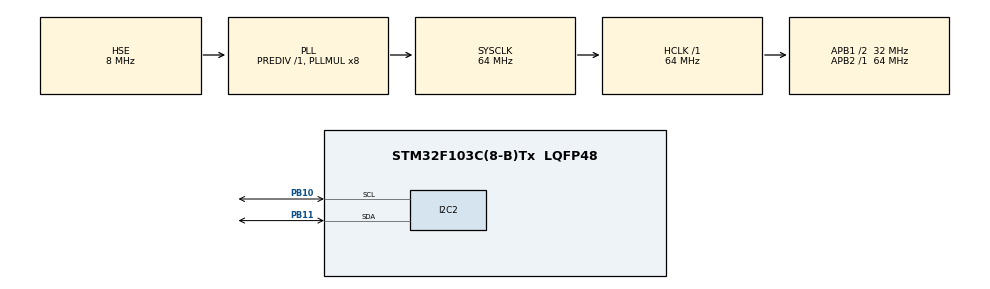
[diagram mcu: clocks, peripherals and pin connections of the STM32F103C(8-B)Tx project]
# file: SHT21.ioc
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Mcu.Family=STM32F1
Mcu.Name=STM32F103C(8-B)Tx
Mcu.Package=LQFP48
NVIC.PriorityGroup=NVIC_PRIORITYGROUP_4
PA13.Mode=Serial_Wire
PA13.Signal=SYS_JTMS-SWDIO
PA14.Mode=Serial_Wire
PA14.Signal=SYS_JTCK-SWCLK
PB10.Mode=I2C
PB10.Signal=I2C2_SCL
PB11.Mode=I2C
PB11.Signal=I2C2_SDA
PD0-OSC_IN.Mode=HSE-External-Oscillator
PD0-OSC_IN.Signal=RCC_OSC_IN
PD1-OSC_OUT.Mode=HSE-External-Oscillator
PD1-OSC_OUT.Signal=RCC_OSC_OUT
ProjectManager.HeapSize=0x2000
ProjectManager.StackSize=0x4000
ProjectManager.TargetToolchain=MDK-ARM V5.27
RCC.AHBFreq_Value=64000000
RCC.APB1CLKDivider=RCC_HCLK_DIV2
RCC.APB1Freq_Value=32000000
RCC.APB1TimFreq_Value=64000000
RCC.APB2Freq_Value=64000000
RCC.APB2TimFreq_Value=64000000
RCC.HCLKFreq_Value=64000000
RCC.PLLMUL=RCC_PLL_MUL8
RCC.PLLSourceVirtual=RCC_PLLSOURCE_HSE
RCC.SYSCLKFreq_VALUE=64000000
RCC.SYSCLKSource=RCC_SYSCLKSOURCE_PLLCLK
RCC.USBFreq_Value=64000000
board=custom

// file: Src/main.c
/* USER CODE BEGIN Header */
/**
  ******************************************************************************
  * @file           : main.c
  * @brief          : Main program body
  ******************************************************************************
  * @attention
  *
  * <h2><center>&copy; Copyright (c) 2020 STMicroelectronics.
  * All rights reserved.</center></h2>
  *
  * This software component is licensed by ST under BSD 3-Clause license,
  * the "License"; You may not use this file except in compliance with the
  * License. You may obtain a copy of the License at:
  *                        opensource.org/licenses/BSD-3-Clause
  *
  ******************************************************************************
  */
/* USER CODE END Header */

#include "main.h"

/* USER CODE BEGIN PD */
uint8_t ph = 0xf5;
uint8_t ud = 0xe7;
uint8_t t =0xf3;
uint8_t re = 0xFE;
/* USER CODE END PD */

I2C_HandleTypeDef hi2c2;

/* USER CODE BEGIN PV */
uint8_t phRXbuff[]={0x00, 0x00, 0x00};
uint8_t TXbuff[]={0x00};
uint8_t tRXbuff[]={0x00, 0x00, 0x00};
uint8_t udRXbuff[]={0x00};
/* USER CODE END PV */

void SystemClock_Config(void);
static void MX_GPIO_Init(void);
static void MX_I2C2_Init(void);

/* USER CODE BEGIN PFP */
float convertph (uint8_t Mnumb,uint8_t Lnumb);
float convertT (uint8_t Mnumb,uint8_t Lnumb);
/* USER CODE END PFP */

int main(void)
{

  /* MCU Configuration--------------------------------------------------------*/

  /* Reset of all peripherals, Initializes the Flash interface and the Systick. */
  HAL_Init();

  /* Configure the system clock */
  SystemClock_Config();

  /* Initialize all configured peripherals */
  MX_GPIO_Init();
  MX_I2C2_Init();
  /* USER CODE BEGIN 2 */
	TXbuff [0] = ph;
	HAL_I2C_Master_Transmit(&hi2c2, (uint16_t)0x80, TXbuff, 1, (uint32_t)1000);
	HAL_Delay (26);
	HAL_I2C_Master_Receive(&hi2c2, (uint16_t)0x80, phRXbuff, 3, (uint32_t)1000);
	float mesph=convertph(phRXbuff[0],phRXbuff[1]);
	HAL_Delay (1000);

	TXbuff [0] = t;
	HAL_I2C_Master_Transmit(&hi2c2, (uint16_t)0x80, TXbuff, 1, (uint32_t)1000);
	HAL_Delay (70);
	HAL_I2C_Master_Receive(&hi2c2, (uint16_t)0x80, tRXbuff, 3, (uint32_t)1000);
	HAL_Delay (1000);
	float MesT=convertT(tRXbuff[0], tRXbuff[1]);
	TXbuff [0] = ud;
	HAL_I2C_Master_Transmit(&hi2c2, (uint16_t)0x80, TXbuff, 1, (uint32_t)1000);
	HAL_Delay (1);
	HAL_I2C_Master_Receive(&hi2c2, (uint16_t)0x80, udRXbuff, 1, (uint32_t)1000);
	HAL_Delay (1000);
  /* USER CODE END 2 */

  /* Infinite loop */
  /* USER CODE BEGIN WHILE */
  while (1)
  {
	HAL_I2C_Master_Transmit(&hi2c2, (uint16_t)0x80, TXbuff, 1, (uint32_t)1000);
//	HAL_Delay (66);
	HAL_I2C_Master_Receive(&hi2c2, (uint16_t)0x80, udRXbuff, 1, (uint32_t)1000);
	HAL_Delay (1000);
		/* USER CODE END WHILE */

  }
}

void SystemClock_Config(void)
{
  RCC_OscInitTypeDef RCC_OscInitStruct = {0};
  RCC_ClkInitTypeDef RCC_ClkInitStruct = {0};

  /** Initializes the CPU, AHB and APB busses clocks
  */
  RCC_OscInitStruct.OscillatorType = RCC_OSCILLATORTYPE_HSE;
  RCC_OscInitStruct.HSEState = RCC_HSE_ON;
  RCC_OscInitStruct.HSEPredivValue = RCC_HSE_PREDIV_DIV1;
  RCC_OscInitStruct.HSIState = RCC_HSI_ON;
  RCC_OscInitStruct.PLL.PLLState = RCC_PLL_ON;
  RCC_OscInitStruct.PLL.PLLSource = RCC_PLLSOURCE_HSE;
  RCC_OscInitStruct.PLL.PLLMUL = RCC_PLL_MUL8;
  if (HAL_RCC_OscConfig(&RCC_OscInitStruct) != HAL_OK)
  {
    Error_Handler();
  }
  /** Initializes the CPU, AHB and APB busses clocks
  */
  RCC_ClkInitStruct.ClockType = RCC_CLOCKTYPE_HCLK|RCC_CLOCKTYPE_SYSCLK
                              |RCC_CLOCKTYPE_PCLK1|RCC_CLOCKTYPE_PCLK2;
  RCC_ClkInitStruct.SYSCLKSource = RCC_SYSCLKSOURCE_PLLCLK;
  RCC_ClkInitStruct.AHBCLKDivider = RCC_SYSCLK_DIV1;
  RCC_ClkInitStruct.APB1CLKDivider = RCC_HCLK_DIV2;
  RCC_ClkInitStruct.APB2CLKDivider = RCC_HCLK_DIV1;

  if (HAL_RCC_ClockConfig(&RCC_ClkInitStruct, FLASH_LATENCY_2) != HAL_OK)
  {
    Error_Handler();
  }
}

static void MX_I2C2_Init(void)
{

  hi2c2.Instance = I2C2;
  hi2c2.Init.ClockSpeed = 100000;
  hi2c2.Init.DutyCycle = I2C_DUTYCYCLE_2;
  hi2c2.Init.OwnAddress1 = 0;
  hi2c2.Init.AddressingMode = I2C_ADDRESSINGMODE_7BIT;
  hi2c2.Init.DualAddressMode = I2C_DUALADDRESS_DISABLE;
  hi2c2.Init.OwnAddress2 = 0;
  hi2c2.Init.GeneralCallMode = I2C_GENERALCALL_DISABLE;
  hi2c2.Init.NoStretchMode = I2C_NOSTRETCH_DISABLE;
  if (HAL_I2C_Init(&hi2c2) != HAL_OK)
  {
    Error_Handler();
  }

}

static void MX_GPIO_Init(void)
{

  /* GPIO Ports Clock Enable */
  __HAL_RCC_GPIOD_CLK_ENABLE();
  __HAL_RCC_GPIOB_CLK_ENABLE();
  __HAL_RCC_GPIOA_CLK_ENABLE();

}

/* USER CODE BEGIN 4 */
float convertph (uint8_t Mnumb,uint8_t Lnumb){
	float Mdec=0,Ldec=0,ph;
	for(uint8_t i=0;i<Mnumb;i++)
	{
		Mdec++;
	}
	for(uint8_t i=0;i<Lnumb;i++)
	{
		Ldec++;
	}
	ph=-6+((125*(256*Mdec+Ldec))/(65536));
	return (ph);
}
float convertT (uint8_t Mnumb,uint8_t Lnumb){
	float Mdec=0,Ldec=0,T;
	for(uint8_t i=0;i<Mnumb;i++)
	{
		Mdec++;
	}
	for(uint8_t i=0;i<Lnumb;i++)
	{
		Ldec++;
	}
	T=-46.85 + (175.72*(256*Mnumb+Lnumb))/65536;
	return (T);
}
/* USER CODE END 4 */

void Error_Handler(void)
{
}

/************************ (C) COPYRIGHT STMicroelectronics *****END OF FILE****/
